VERSION ""

NS_ :

BS_:

BU_: XXX DSU HCU EPS IPAS

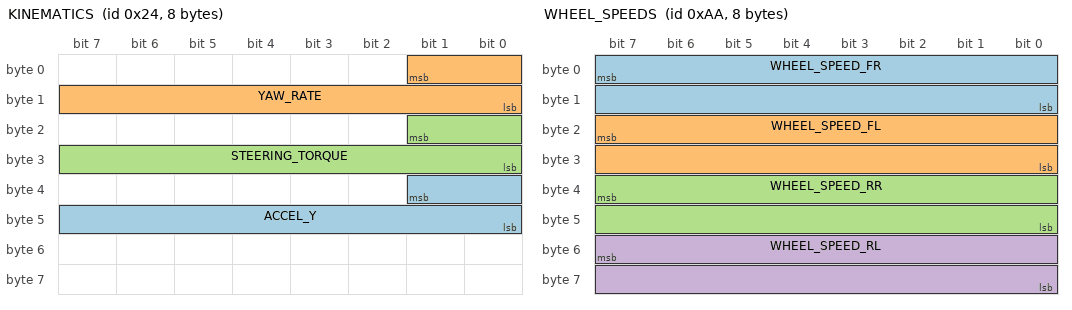
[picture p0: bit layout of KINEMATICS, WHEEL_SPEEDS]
BO_ 36 KINEMATICS: 8 XXX
 SG_ ACCEL_Y : 33|10@0+ (1,-512) [0|65535] "" XXX
 SG_ YAW_RATE : 1|10@0+ (1,-512) [0|65535] "" XXX
 SG_ STEERING_TORQUE : 17|10@0+ (1,-512) [0|65535] "" XXX

BO_ 170 WHEEL_SPEEDS: 8 XXX
 SG_ WHEEL_SPEED_FR : 7|16@0+ (0.01,-67.67) [0|250] "kph" XXX
 SG_ WHEEL_SPEED_FL : 23|16@0+ (0.01,-67.67) [0|250] "kph" XXX
 SG_ WHEEL_SPEED_RR : 39|16@0+ (0.01,-67.67) [0|250] "kph" XXX
 SG_ WHEEL_SPEED_RL : 55|16@0+ (0.01,-67.67) [0|250] "kph" XXX

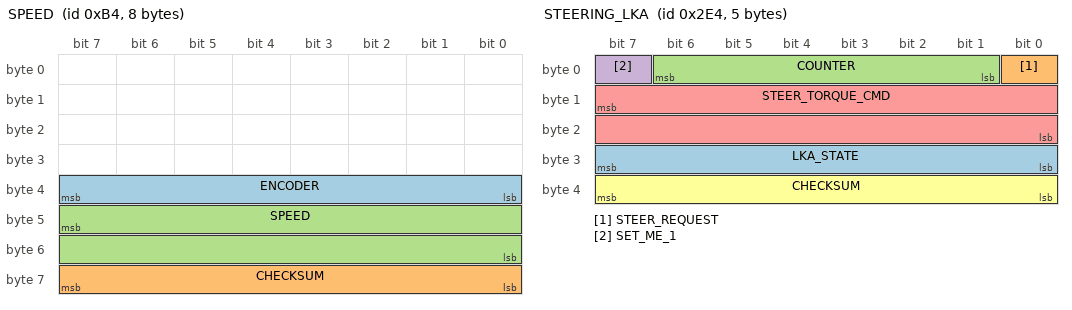
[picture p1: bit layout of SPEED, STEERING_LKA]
BO_ 180 SPEED: 8 XXX
 SG_ ENCODER : 39|8@0+ (1,0) [0|255] "" XXX
 SG_ CHECKSUM : 63|8@0+ (1,0) [0|255] "" XXX
 SG_ SPEED : 47|16@0+ (0.01,0) [0|250] "kph" XXX

BO_ 560 BRAKE_MODULE2: 7 XXX
 SG_ BRAKE_PRESSED : 26|1@0+ (1,0) [0|1] "" XXX

BO_ 740 STEERING_LKA: 5 XXX
 SG_ LKA_STATE : 31|8@0+ (1,0) [0|255] "" XXX
 SG_ STEER_REQUEST : 0|1@0+ (1,0) [0|1] "" XXX
 SG_ COUNTER : 6|6@0+ (1,0) [0|63] "" XXX
 SG_ SET_ME_1 : 7|1@0+ (1,0) [0|1] "" XXX
 SG_ STEER_TORQUE_CMD : 15|16@0- (1,0) [0|65535] "" XXX
 SG_ CHECKSUM : 39|8@0+ (1,0) [0|255] "" XXX

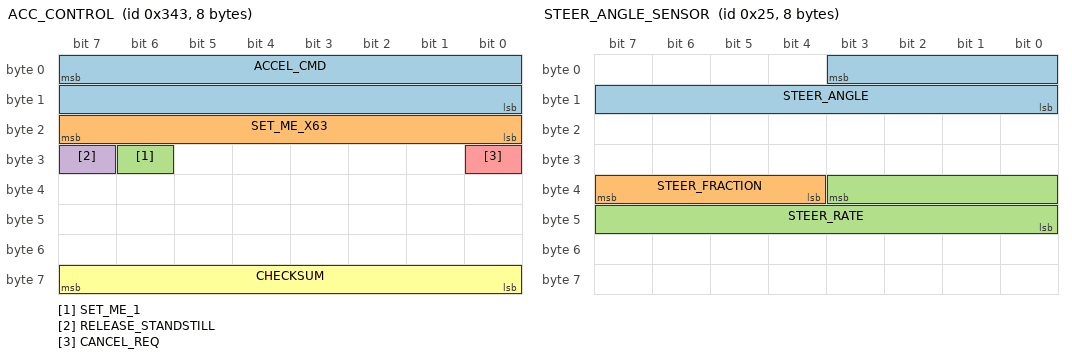
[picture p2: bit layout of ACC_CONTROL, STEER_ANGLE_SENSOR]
BO_ 835 ACC_CONTROL: 8 DSU
 SG_ ACCEL_CMD : 7|16@0- (0.001,0) [-20|20] "m/s2" HCU
 SG_ SET_ME_X63 : 23|8@0+ (1,0) [0|255] "" HCU
 SG_ SET_ME_1 : 30|1@0+ (1,0) [0|1] "" HCU
 SG_ RELEASE_STANDSTILL : 31|1@0+ (1,0) [0|1] "" HCU
 SG_ CANCEL_REQ : 24|1@0+ (1,0) [0|1] "" HCU
 SG_ CHECKSUM : 63|8@0+ (1,0) [0|255] "" XXX

BO_ 37 STEER_ANGLE_SENSOR: 8 XXX
 SG_ STEER_ANGLE : 3|12@0- (1.5,0) [-500|500] "deg" XXX
 SG_ STEER_FRACTION : 39|4@0- (0.1,0) [-0.7|0.7] "deg" XXX
 SG_ STEER_RATE : 35|12@0- (1,0) [-2000|2000] "deg/s" XXX

BO_ 921 PCM_CRUISE_SM: 8 XXX
 SG_ UI_SET_SPEED : 31|8@0+ (1,0) [0|255] "" XXX
 SG_ CRUISE_ENGAGED : 9|1@0+ (1,0) [0|1] "" XXX

BO_ 951 ESP_CONTROL: 8 ESP
 SG_ TC_DISABLED : 13|1@0+ (1,0) [0|1] "" XXX
 SG_ BRAKE_LIGHTS_ACC : 18|1@0+ (1,0) [0|1] "" XXX

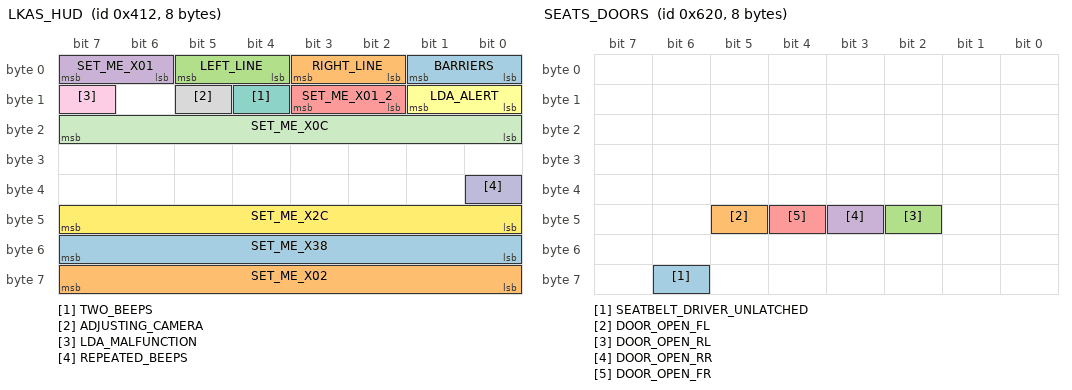
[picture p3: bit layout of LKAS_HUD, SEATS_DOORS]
BO_ 1042 LKAS_HUD: 8 XXX
 SG_ BARRIERS : 1|2@0+ (1,0) [0|3] "" XXX
 SG_ RIGHT_LINE : 3|2@0+ (1,0) [0|3] "" XXX
 SG_ LEFT_LINE : 5|2@0+ (1,0) [0|3] "" XXX
 SG_ SET_ME_X01 : 7|2@0+ (1,0) [0|3] "" XXX
 SG_ SET_ME_X01_2 : 11|2@0+ (1,0) [0|3] "" XXX
 SG_ LDA_ALERT : 9|2@0+ (1,0) [0|3] "" XXX
 SG_ TWO_BEEPS : 12|1@0+ (1,0) [0|1] "" XXX
 SG_ ADJUSTING_CAMERA : 13|1@0+ (1,0) [0|1] "" XXX
 SG_ LDA_MALFUNCTION : 15|1@0+ (1,0) [0|1] "" XXX
 SG_ REPEATED_BEEPS : 32|1@0+ (1,0) [0|1] "" XXX
 SG_ SET_ME_X0C : 23|8@0+ (1,0) [0|1] "" XXX
 SG_ SET_ME_X2C : 47|8@0+ (1,0) [0|1] "" XXX
 SG_ SET_ME_X38 : 55|8@0+ (1,0) [0|1] "" XXX
 SG_ SET_ME_X02 : 63|8@0+ (1,0) [0|1] "" XXX

BO_ 1553 UI_SEETING: 8 XXX
 SG_ UNITS : 26|2@0+ (1,0) [0|3] "" XXX

BO_ 1568 SEATS_DOORS: 8 XXX
 SG_ SEATBELT_DRIVER_UNLATCHED : 62|1@0+ (1,0) [0|1] "" XXX
 SG_ DOOR_OPEN_FL : 45|1@0+ (1,0) [0|1] "" XXX
 SG_ DOOR_OPEN_RL : 42|1@0+ (1,0) [0|1] "" XXX
 SG_ DOOR_OPEN_RR : 43|1@0+ (1,0) [0|1] "" XXX
 SG_ DOOR_OPEN_FR : 44|1@0+ (1,0) [0|1] "" XXX

BO_ 1570 LIGHT_STALK: 8 SCM
 SG_ AUTO_HIGH_BEAM : 37|1@0+ (1,0) [0|1] "" XXX

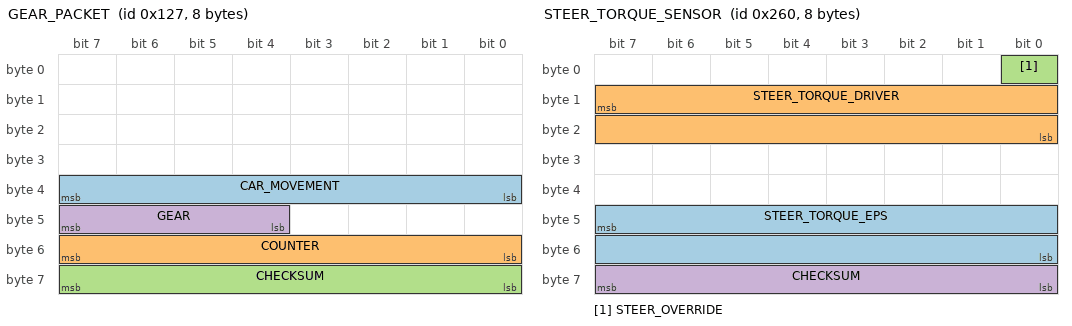
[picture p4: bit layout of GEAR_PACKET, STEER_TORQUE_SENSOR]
BO_ 295 GEAR_PACKET: 8 XXX
 SG_ CAR_MOVEMENT : 39|8@0- (1,0) [0|255] "" XXX
 SG_ COUNTER : 55|8@0+ (1,0) [0|255] "" XXX
 SG_ CHECKSUM : 63|8@0+ (1,0) [0|255] "" XXX
 SG_ GEAR : 47|4@0+ (1,0) [0|15] "" XXX

BO_ 581 GAS_PEDAL: 8 XXX
 SG_ GAS_PEDAL : 23|8@0+ (0.005,0) [0|1] "" XXX

BO_ 608 STEER_TORQUE_SENSOR: 8 XXX
 SG_ STEER_TORQUE_EPS : 47|16@0- (0.66,0) [-20000|20000] "" XXX
 SG_ STEER_TORQUE_DRIVER : 15|16@0- (1,0) [-32768|32767] "" XXX
 SG_ STEER_OVERRIDE : 0|1@0+ (1,0) [0|1] "" XXX
 SG_ CHECKSUM : 63|8@0+ (1,0) [0|255] "" XXX

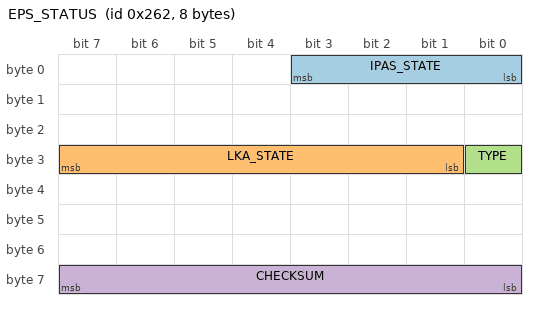
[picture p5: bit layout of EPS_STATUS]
BO_ 610 EPS_STATUS: 8 EPS
 SG_ IPAS_STATE : 3|4@0+ (1,0) [0|15] "" XXX
 SG_ LKA_STATE : 31|7@0+ (1,0) [0|127] "" XXX
 SG_ TYPE : 24|1@0+ (1,0) [0|1] "" XXX
 SG_ CHECKSUM : 63|8@0+ (1,0) [0|255] "" XXX
